# STM32U3B5 register map
File version: 1.0
CPU: CM33 r0p1, little endian, MPU, FPU, 4 interrupt priority bits
Registers are 32-bit, read-write, reset 0x0 unless marked. A register's access mark holds for its fields unless they carry their own. Offsets are from the block's base; [hi:lo] are bit positions; {n}, {i} and the like mark numbered series; 'fields as' and 'values as' point back to an identical list.

## EXTI — EXTI register block
Base 0x40032000
Same registers: SEC_ExTI 0x50032000
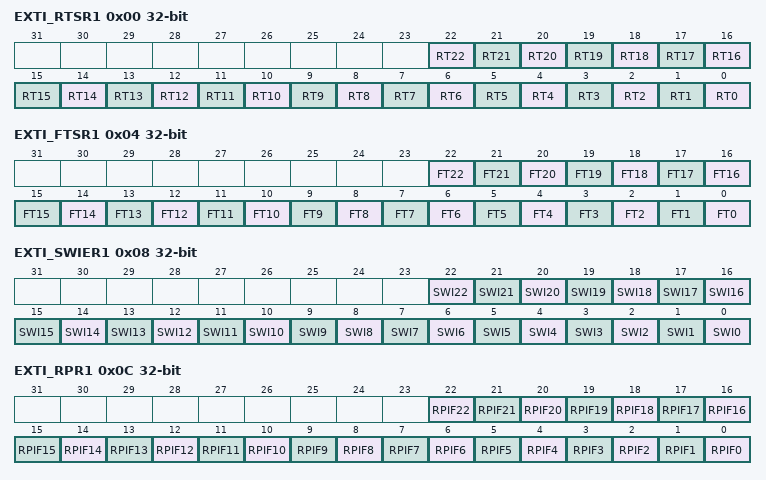
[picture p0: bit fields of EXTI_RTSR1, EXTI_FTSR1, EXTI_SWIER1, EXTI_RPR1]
0x00 EXTI_RTSR1 — EXTI rising trigger selection register
  [all] fields
    0=Rising trigger disabled (for event and interrupt) for input line; 1=Rising trigger enabled (for event and interrupt) for input line
  [n] RT{n} (n=0..22) — Rising trigger event configuration bit of configurable event input i
0x04 EXTI_FTSR1 — EXTI falling trigger selection register
  [all] fields
    0=Falling trigger disabled (for event and interrupt) for input line; 1=Falling trigger enabled (for event and interrupt) for input line
  [n] FT{n} (n=0..22) — Falling trigger event configuration bit of configurable event input i
0x08 EXTI_SWIER1 — EXTI software interrupt event register
  [all] fields
    0=Writing 0 has no effect; 1=Writing 1 triggers a rising edge event on event i
  [n] SWI{n} (n=0..22) — Software interrupt on event i
0x0C EXTI_RPR1 — EXTI rising edge pending register
  [all] fields
    0=No rising edge trigger request occurred; 1=Rising edge trigger request occurred
  [n] RPIF{n} (n=0..22) — Configurable event input i rising edge pending bit
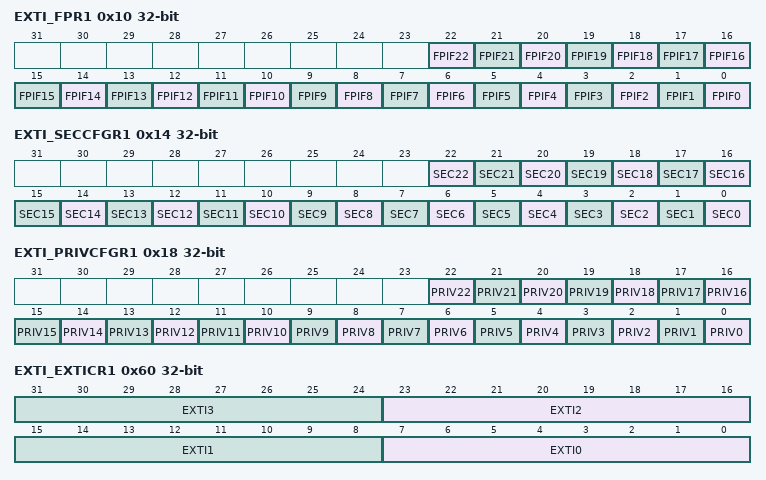
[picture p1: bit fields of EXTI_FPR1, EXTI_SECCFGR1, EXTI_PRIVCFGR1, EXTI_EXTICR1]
0x10 EXTI_FPR1 — EXTI falling edge pending register
  [all] fields
    0=No falling edge trigger request occurred; 1=Falling edge trigger request occurred
  [n] FPIF{n} (n=0..22) — configurable event inputs i falling edge pending bit
0x14 EXTI_SECCFGR1 — EXTI security configuration register
  [all] fields
    0=Event security disabled (nonsecure); 1=Event security enabled (secure)
  [n] SEC{n} (n=0..22) — Security enable on event input i
0x18 EXTI_PRIVCFGR1 — EXTI privilege configuration register
  [all] fields
    0=Event privilege disabled (unprivileged); 1=Event privilege enabled (privileged)
  [n] PRIV{n} (n=0..22) — Security enable on event input i
0x60 EXTI_EXTICR1 — EXTI external interrupt selection register
  [8n+7:8n] EXTI{n} (n=0..3) — EXTI{n} GPIO port selection
    0=PA[{n}] pin; 1=PB[{n}] pin; 2=PC[{n}] pin; 3=PD[{n}] pin; 4=PE[{n}] pin; 5=PF[{n}] pin; 6=PG[{n}] pin; 7=PH[{n}] pin
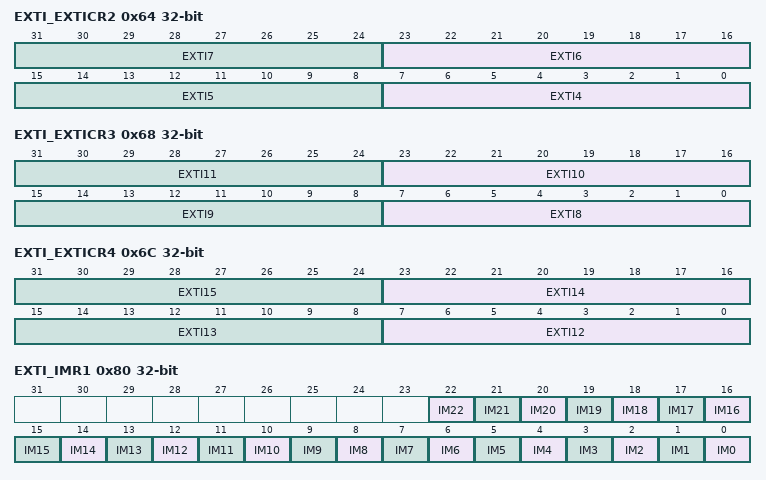
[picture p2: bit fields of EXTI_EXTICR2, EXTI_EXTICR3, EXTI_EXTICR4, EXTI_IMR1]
0x64 EXTI_EXTICR2 — EXTI external interrupt selection register
  [8n-25:8n-32] EXTI{n} (n=4..7) — EXTI{n} GPIO port selection
    values as EXTI_EXTICR1.EXTI0
0x68 EXTI_EXTICR3 — EXTI external interrupt selection register
  [8n-57:8n-64] EXTI{n} (n=8..11) — EXTI{n} GPIO port selection
    values as EXTI_EXTICR1.EXTI0
0x6C EXTI_EXTICR4 — EXTI external interrupt selection register
  [8n-89:8n-96] EXTI{n} (n=12..15) — EXTI{n} GPIO port selection
    values as EXTI_EXTICR1.EXTI0
0x70 EXTI_LOCKR — EXTI lock register
  [0] LOCK — Global security and privilege configuration registers (EXTI_SECCFGR and EXTI_PRIVCFGR) lock
    0=Security and privilege configuration open, can be modified; 1=Security and privilege configuration locked, can no longer be modified
0x80 EXTI_IMR1 — EXTI CPU wake-up with interrupt mask register
  [all] fields
    0=Wake-up with interrupt request from input event i is masked; 1=Wake-up with interrupt request from input event i is unmasked
  [n] IM{n} (n=0..22) — CPU wake-up with interrupt mask on event input i
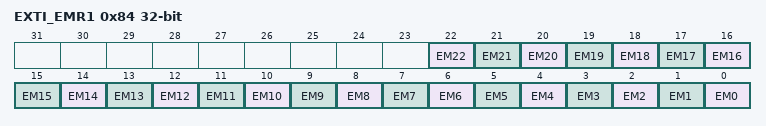
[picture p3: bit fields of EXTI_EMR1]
0x84 EXTI_EMR1 — EXTI CPU wake-up with event mask register
  [all] fields
    0=Wake-up with event generation from line i is masked; 1=Wake-up with event generation from line i is unmasked
  [n] EM{n} (n=0..22) — CPU wake-up with event generation mask on event input i

## GTZC1_MPCBB1 — GTZC1_MPCBB1 address block description
Base 0x40032C00
Same registers: SEC_GTZC1_MPCBB1 0x50032C00
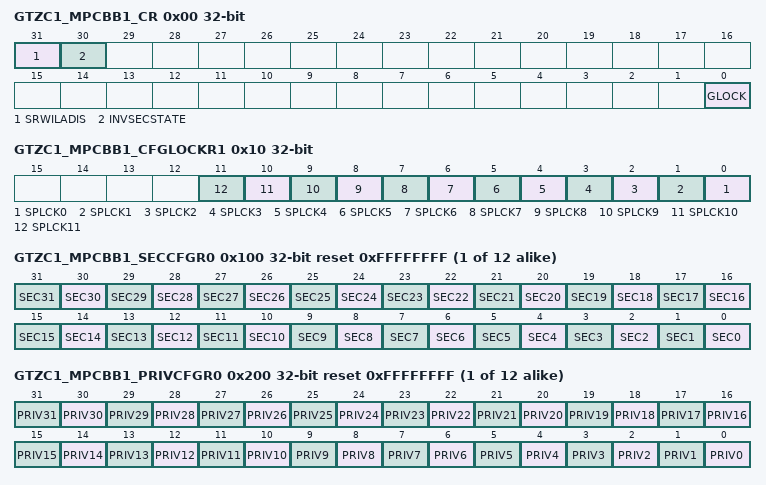
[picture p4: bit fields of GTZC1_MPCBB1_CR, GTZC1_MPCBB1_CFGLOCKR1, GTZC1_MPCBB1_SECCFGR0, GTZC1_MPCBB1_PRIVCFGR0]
0x00 GTZC1_MPCBB1_CR (alternate view of GTZC1_TZSC_CR) — GTZC1 SRAM1 MPCBB control register
  [31] SRWILADIS — Secure read/write illegal access disable
    0=Enabled, secure read/write access not allowed on nonsecure SRAM block; 1=Disabled, secure read/write access allowed on nonsecure SRAM block
  [30] INVSECSTATE — SRAM1 clock security state
    0=SRAM clocks are secure if a secure area exists in the MPCBB, and nonsecure if there is no secure area; 1=SRAM clocks are nonsecure even if a secure area exists in the MPCBB, and secure even if no secure block is set in the MPCBB
  [0] GLOCK — Lock the control register of the MPCBB until next reset
    0=Control register not locked; 1=Control register locked
0x10 GTZC1_MPCBB1_CFGLOCKR1 (alternate view of GTZC1_TZSC_SECCFGR1) — GTZC1 SRAM1 MPCBB configuration lock register 1
  [all] fields
    0=GTZC1_MPCBB1_SECCFGRi and GTZC1_MPCBB1_PRIVCFGRi can be written; 1=Writes to GTZC1_MPCBB1_SECCFGRi and GTZC1_MPCBB1_PRIVCFGRi are ignored
  [n] SPLCK{n} (n=0..11) — Security/privilege configuration lock for super-block i
{0x100+4i} GTZC1_MPCBB1_SECCFGR{i} reset 0xFFFFFFFF (i=0..11) — GTZC1 SRAM1 MPCBB security configuration for super-block {i} register
  [all] fields
    0=Nonsecure access only to block i, belonging to super-block x; 1=Secure access only to block i, belonging to super-block x
  [n] SEC{n} (n=0..31) — Security configuration for block i
{0x200+4i} GTZC1_MPCBB1_PRIVCFGR{i} reset 0xFFFFFFFF (i=0..11) — GTZC1 SRAM1 MPCBB privileged configuration for super-block {i} register
  [all] fields
    0=Privileged and unprivileged access to block i, belonging to super-block x; 1=Only privileged access to block i, belonging to super-block x
  [n] PRIV{n} (n=0..31) — Privileged configuration for block i, belonging to super-block x
